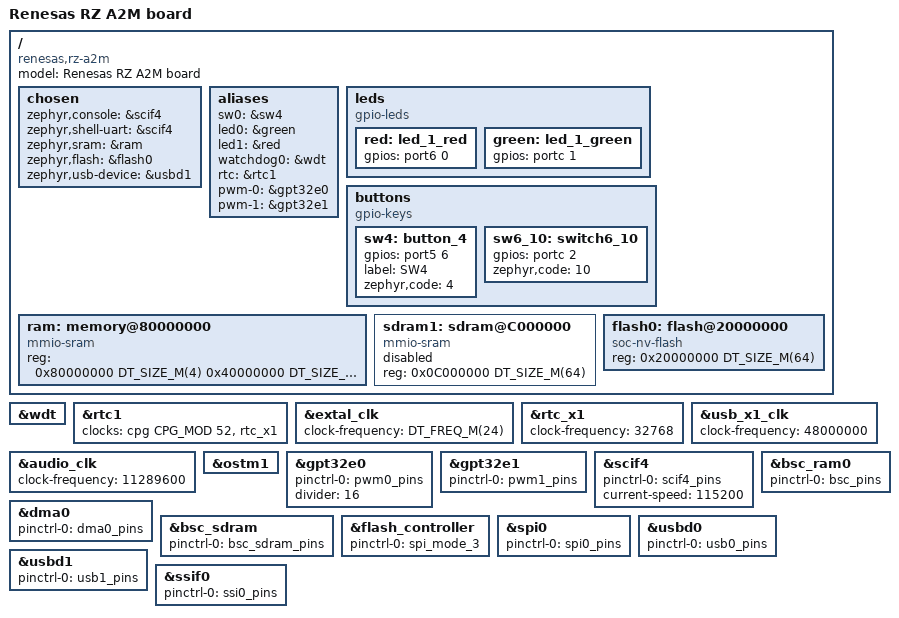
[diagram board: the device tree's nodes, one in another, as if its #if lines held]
/*
 * Copyright (c) 2023 EPAM Systems
 *
 * SPDX-License-Identifier: Apache-2.0
 */

/dts-v1/;
#include <arm/renesas/rz/r7s9210.dtsi>
#include <freq.h>
#include "rz_a2m_pinctrl.dtsi"
#include "rz_a2m_eth.dtsi"

/ {
	model = "Renesas RZ A2M board";
	compatible = "renesas,rz-a2m";

	chosen {
		zephyr,console = &scif4;
		zephyr,shell-uart = &scif4;
		zephyr,sram = &ram;
		zephyr,flash = &flash0;
		zephyr,usb-device = &usbd1;
	};

	aliases {
		sw0 = &sw4;
		led0 = &green;
		led1 = &red;
		watchdog0 = &wdt;
		rtc = &rtc1;
		pwm-0 = &gpt32e0;
		pwm-1 = &gpt32e1;
	};

	leds {
		compatible = "gpio-leds";
		red: led_1_red {
			gpios = <&port6 0 GPIO_ACTIVE_HIGH>;
		};

		green: led_1_green {
			gpios = <&portc 1 GPIO_ACTIVE_HIGH>;
		};
	};

	buttons {
		compatible = "gpio-keys";
		sw4: button_4 {
		     gpios = <&port5 6 GPIO_ACTIVE_HIGH>;
		     label = "SW4";
		     zephyr,code = <4>;
		};

		sw6_10: switch6_10 {
		     gpios = <&portc 2 GPIO_ACTIVE_HIGH>;
		     zephyr,code = <10>;
		};
	};

#ifdef CONFIG_XIP
	ram: memory@80000000 {
		compatible = "mmio-sram";
		reg = <0x80000000 DT_SIZE_M(4)		 /* 4  Mbyte of Internal RAM */
		       0x40000000 DT_SIZE_M(8)>;	 /* 8  Mbyte of External HyperRAM */
	};
#else
	/* TODO: Remove this when RECRZZP-52 is resolved */
	ram: memory@80020000 {
		compatible = "mmio-sram";
		reg = <0x80020000 DT_SIZE_K(3968)>;
	};
#endif
	/*
	 * Enable this node if SDRAM is connected
	 * You must change switch SW6_1 to "ON" to enable SDRAM bus
	 * You must also change switch SW6_3 to "ON to detach USB-serial from SDRAM bus
	 * You must also change switch SW6_4 to "OFF" to enable SCIF-2 on CN17
	 */
	sdram1: sdram@C000000 {
		compatible = "mmio-sram";
		reg = <0x0C000000 DT_SIZE_M(64)>;
		status = "disabled";
	};

#ifdef CONFIG_XIP
	flash0: flash@20000000 {
		compatible = "soc-nv-flash";
		reg = <0x20000000 DT_SIZE_M(64)>;
	};
#else
	flash_controller: flash-controller@1F800000 {
		compatible = "renesas,rza2-flash-controller";
		reg = <0x1F800000 0x78>;

		#address-cells = <1>;
		#size-cells = <1>;
		flash0: flash@20000000 {
			compatible = "soc-nv-flash";
			reg = <0x20000000 DT_SIZE_M(64)>;
			erase-block-size = <4096>;
			write-block-size = <256>;
		};
	};
#endif
};

&wdt {
	status = "okay";
};

&rtc1 {
	status = "okay";
	clocks = <&cpg CPG_MOD 52>, <&rtc_x1>;
};

&extal_clk {
	clock-frequency = <DT_FREQ_M(24)>;
};

&rtc_x1 {
	clock-frequency = <32768>;
};

/* USB_X1 */
&usb_x1_clk {
	clock-frequency = <48000000>;
};

/* Audio clock */
&audio_clk {
	clock-frequency = <11289600>;
};

&ostm1 {
	status = "okay";
};

&gpt32e0 {
	pinctrl-0 = <&pwm0_pins>;
	pinctrl-names = "default";
	divider = <16>;
	status = "okay";
};

&gpt32e1 {
	pinctrl-0 = <&pwm1_pins>;
	pinctrl-names = "default";
	status = "okay";
};

&scif4 {
	pinctrl-0 = <&scif4_pins>;
	pinctrl-names = "default";
	current-speed = <115200>;
	status = "okay";
};


&dma0 {
	pinctrl-0 = <&dma0_pins>;
	pinctrl-names = "default";
};

&bsc_ram0 {
	pinctrl-0 = <&bsc_pins>;
	pinctrl-names = "default";
};

&bsc_sdram {
	pinctrl-0 = <&bsc_sdram_pins>;
	pinctrl-names = "default";
};

#ifndef CONFIG_XIP
&flash_controller {
	pinctrl-0 = <&spi_mode_3>;
	pinctrl-names = "default";
};
#endif

&spi0 {
	pinctrl-0 = <&spi0_pins>;
	pinctrl-names = "default";
};

&usbd0 {
	pinctrl-0 = <&usb0_pins>;
	pinctrl-names = "default";
};

&usbd1 {
	pinctrl-0 = <&usb1_pins>;
	pinctrl-names = "default";
};

&ssif0 {
	pinctrl-0 = <&ssi0_pins>;
	pinctrl-names = "default";
};
